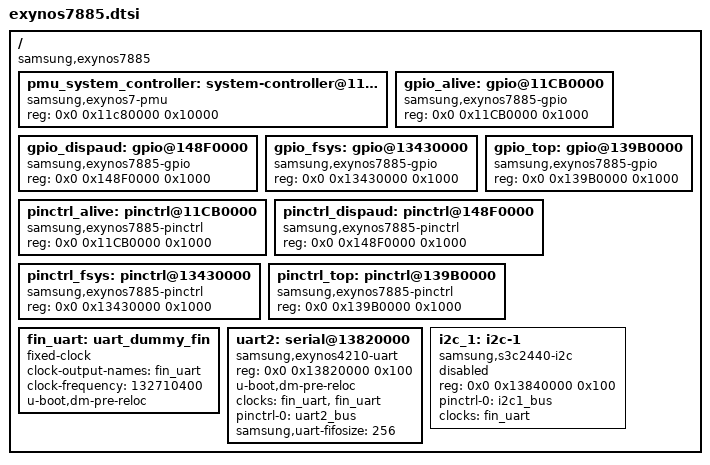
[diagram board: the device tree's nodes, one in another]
// SPDX-License-Identifier: GPL-2.0+
/*
 * Samsung Exynos7885 SoC device tree source
 *
 * Copyright (c) 2023 Dávid Virág (virag.david003@gmail.com)
 */

/dts-v1/;
#include <dt-bindings/interrupt-controller/arm-gic.h>
/ {
	compatible = "samsung,exynos7885";
	#address-cells = <2>;
	#size-cells = <1>;

	pmu_system_controller: system-controller@11c80000 {
		compatible = "samsung,exynos7-pmu", "syscon";
		reg = <0x0 0x11c80000 0x10000>;
	};

	gpio_alive: gpio@11CB0000 {
		compatible = "samsung,exynos7885-gpio";
		reg = <0x0 0x11CB0000 0x1000>;
	};

	gpio_dispaud: gpio@148F0000 {
		compatible = "samsung,exynos7885-gpio";
		reg = <0x0 0x148F0000 0x1000>;
	};

	gpio_fsys: gpio@13430000 {
		compatible = "samsung,exynos7885-gpio";
		reg = <0x0 0x13430000 0x1000>;
	};

	gpio_top: gpio@139B0000 {
		compatible = "samsung,exynos7885-gpio";
		reg = <0x0 0x139B0000 0x1000>;
	};

	pinctrl_alive: pinctrl@11CB0000 {
		compatible = "samsung,exynos7885-pinctrl";
		reg = <0x0 0x11CB0000 0x1000>;
	};

	pinctrl_dispaud: pinctrl@148F0000 {
		compatible = "samsung,exynos7885-pinctrl";
		reg = <0x0 0x148F0000 0x1000>;
	};

	pinctrl_fsys: pinctrl@13430000 {
		compatible = "samsung,exynos7885-pinctrl";
		reg = <0x0 0x13430000 0x1000>;
	};

	pinctrl_top: pinctrl@139B0000 {
		compatible = "samsung,exynos7885-pinctrl";
		reg = <0x0 0x139B0000 0x1000>;
	};

	/* Dummy clock for uart, TODO proper driver */
	fin_uart: uart_dummy_fin {
		compatible = "fixed-clock";
		clock-output-names = "fin_uart";
		clock-frequency = <132710400>;
		u-boot,dm-pre-reloc;
		#clock-cells = <0>;
	};

	uart2: serial@13820000 {
		compatible = "samsung,exynos4210-uart";
		reg = <0x0 0x13820000 0x100>;
		u-boot,dm-pre-reloc;
		clocks = <&fin_uart>, <&fin_uart>;
		clock-names = "uart", "clk_uart_baud0";
		pinctrl-names = "default";
		pinctrl-0 = <&uart2_bus>;
		samsung,uart-fifosize = <256>;
	};

	i2c_1: i2c-1 {
		compatible = "samsung,s3c2440-i2c";
		reg = <0x0 0x13840000 0x100>;
		#address-cells = <1>;
		#size-cells = <0>;
		pinctrl-names = "default";
		pinctrl-0 = <&i2c1_bus>;
		clocks = <&fin_uart>;
		clock-names = "i2c";
		status = "disabled";
	};
};

#include "exynos7885-pinctrl.dtsi"
#include "exynos7885-gpio.dtsi"
#include "exynos-syscon-restart.dtsi"
